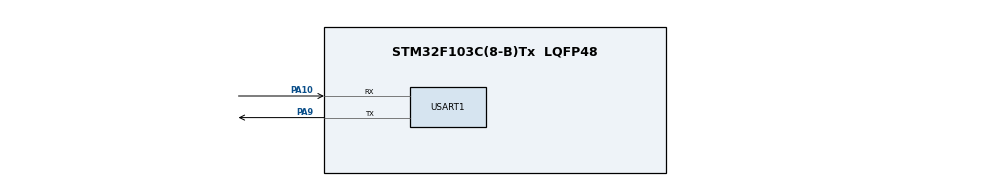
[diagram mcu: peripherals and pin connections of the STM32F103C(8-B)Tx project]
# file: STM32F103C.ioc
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Dma.Request0=USART1_RX
Dma.Request1=USART1_TX
Dma.USART1_RX.0.Direction=DMA_PERIPH_TO_MEMORY
Dma.USART1_RX.0.Instance=DMA1_Channel5
Dma.USART1_RX.0.MemDataAlignment=DMA_MDATAALIGN_BYTE
Dma.USART1_RX.0.MemInc=DMA_MINC_ENABLE
Dma.USART1_RX.0.Mode=DMA_CIRCULAR
Dma.USART1_RX.0.PeriphDataAlignment=DMA_PDATAALIGN_BYTE
Dma.USART1_RX.0.PeriphInc=DMA_PINC_DISABLE
Dma.USART1_RX.0.Priority=DMA_PRIORITY_LOW
Dma.USART1_TX.1.Direction=DMA_MEMORY_TO_PERIPH
Dma.USART1_TX.1.Instance=DMA1_Channel4
Dma.USART1_TX.1.MemDataAlignment=DMA_MDATAALIGN_BYTE
Dma.USART1_TX.1.MemInc=DMA_MINC_ENABLE
Dma.USART1_TX.1.Mode=DMA_NORMAL
Dma.USART1_TX.1.PeriphDataAlignment=DMA_PDATAALIGN_BYTE
Dma.USART1_TX.1.PeriphInc=DMA_PINC_DISABLE
Dma.USART1_TX.1.Priority=DMA_PRIORITY_LOW
Mcu.Family=STM32F1
Mcu.Name=STM32F103C(8-B)Tx
Mcu.Package=LQFP48
NVIC.DMA1_Channel4_IRQn=true\:0\:0\:false\:false\:true\:false\:true
NVIC.DMA1_Channel5_IRQn=true\:0\:0\:false\:false\:true\:false\:true
NVIC.PriorityGroup=NVIC_PRIORITYGROUP_4
NVIC.USART1_IRQn=true\:0\:0\:false\:false\:true\:true\:true
PA10.Mode=Asynchronous
PA10.Signal=USART1_RX
PA13.Mode=Serial_Wire
PA13.Signal=SYS_JTMS-SWDIO
PA14.Mode=Serial_Wire
PA14.Signal=SYS_JTCK-SWCLK
PA9.Mode=Asynchronous
PA9.Signal=USART1_TX
PD0-OSC_IN.Mode=HSE-External-Oscillator
PD0-OSC_IN.Signal=RCC_OSC_IN
PD1-OSC_OUT.Mode=HSE-External-Oscillator
PD1-OSC_OUT.Signal=RCC_OSC_OUT
ProjectManager.HeapSize=0x200
ProjectManager.StackSize=0x400
ProjectManager.TargetToolchain=MDK-ARM V5.27
RCC.AHBFreq_Value=72000000
RCC.APB1CLKDivider=RCC_HCLK_DIV2
RCC.APB1Freq_Value=36000000
RCC.APB1TimFreq_Value=72000000
RCC.APB2Freq_Value=72000000
RCC.APB2TimFreq_Value=72000000
RCC.HCLKFreq_Value=72000000
RCC.PLLMUL=RCC_PLL_MUL9
RCC.PLLSourceVirtual=RCC_PLLSOURCE_HSE
RCC.SYSCLKFreq_VALUE=72000000
RCC.SYSCLKSource=RCC_SYSCLKSOURCE_PLLCLK
RCC.USBFreq_Value=72000000
USART1.VirtualMode=VM_ASYNC
board=custom

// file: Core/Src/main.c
/* USER CODE BEGIN Header */
/**
  ******************************************************************************
  * @file           : main.c
  * @brief          : Main program body
  ******************************************************************************
  * @attention
  *
  * <h2><center>&copy; Copyright (c) 2021 STMicroelectronics.
  * All rights reserved.</center></h2>
  *
  * This software component is licensed by ST under BSD 3-Clause license,
  * the "License"; You may not use this file except in compliance with the
  * License. You may obtain a copy of the License at:
  *                        opensource.org/licenses/BSD-3-Clause
  *
  ******************************************************************************
  */
/* USER CODE END Header */
#include "main.h"
#include "dma.h"
#include "usart.h"
#include "gpio.h"

/* USER CODE BEGIN Includes */
#include "init.h"

/* USER CODE END Includes */

void SystemClock_Config(void);

int main(void)
{

  /* MCU Configuration--------------------------------------------------------*/

  /* Reset of all peripherals, Initializes the Flash interface and the Systick. */

  LL_APB2_GRP1_EnableClock(LL_APB2_GRP1_PERIPH_AFIO);
  LL_APB1_GRP1_EnableClock(LL_APB1_GRP1_PERIPH_PWR);

  NVIC_SetPriorityGrouping(NVIC_PRIORITYGROUP_4);

  /* System interrupt init*/

  /** NOJTAG: JTAG-DP Disabled and SW-DP Enabled
  */
  LL_GPIO_AF_Remap_SWJ_NOJTAG();

  /* Configure the system clock */
  SystemClock_Config();

  /* Initialize all configured peripherals */
  MX_GPIO_Init();
  MX_DMA_Init();
  MX_USART1_UART_Init();
  /* USER CODE BEGIN 2 */
  hal_init();
  usart_send_string("USE DMA: HT & TC + USART IDLE interrupts\r\n");
  /* USER CODE END 2 */

  /* Infinite loop */
  while (1)
  {

  }
}

void SystemClock_Config(void)
{
  LL_FLASH_SetLatency(LL_FLASH_LATENCY_2);
  while(LL_FLASH_GetLatency()!= LL_FLASH_LATENCY_2)
  {
  }
  LL_RCC_HSE_Enable();

   /* Wait till HSE is ready */
  while(LL_RCC_HSE_IsReady() != 1)
  {

  }
  LL_RCC_PLL_ConfigDomain_SYS(LL_RCC_PLLSOURCE_HSE_DIV_1, LL_RCC_PLL_MUL_9);
  LL_RCC_PLL_Enable();

   /* Wait till PLL is ready */
  while(LL_RCC_PLL_IsReady() != 1)
  {

  }
  LL_RCC_SetAHBPrescaler(LL_RCC_SYSCLK_DIV_1);
  LL_RCC_SetAPB1Prescaler(LL_RCC_APB1_DIV_2);
  LL_RCC_SetAPB2Prescaler(LL_RCC_APB2_DIV_1);
  LL_RCC_SetSysClkSource(LL_RCC_SYS_CLKSOURCE_PLL);

   /* Wait till System clock is ready */
  while(LL_RCC_GetSysClkSource() != LL_RCC_SYS_CLKSOURCE_STATUS_PLL)
  {

  }
  LL_Init1msTick(72000000);
  LL_SetSystemCoreClock(72000000);
}

void Error_Handler(void)
{
  __disable_irq();
  while (1)
  {
  }
}

/************************ (C) COPYRIGHT STMicroelectronics *****END OF FILE****/
